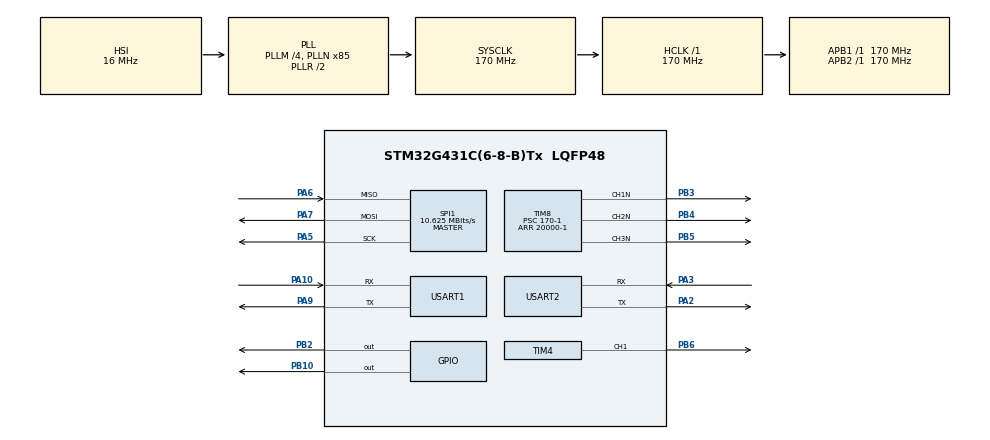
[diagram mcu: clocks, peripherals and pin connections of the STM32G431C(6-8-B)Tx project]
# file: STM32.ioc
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Dma.Request0=USART1_RX
Dma.USART1_RX.0.Direction=DMA_PERIPH_TO_MEMORY
Dma.USART1_RX.0.EventEnable=DISABLE
Dma.USART1_RX.0.Instance=DMA1_Channel1
Dma.USART1_RX.0.MemDataAlignment=DMA_MDATAALIGN_BYTE
Dma.USART1_RX.0.MemInc=DMA_MINC_ENABLE
Dma.USART1_RX.0.Mode=DMA_CIRCULAR
Dma.USART1_RX.0.PeriphDataAlignment=DMA_PDATAALIGN_BYTE
Dma.USART1_RX.0.PeriphInc=DMA_PINC_DISABLE
Dma.USART1_RX.0.Polarity=HAL_DMAMUX_REQ_GEN_RISING
Dma.USART1_RX.0.Priority=DMA_PRIORITY_LOW
Dma.USART1_RX.0.RequestNumber=1
Dma.USART1_RX.0.SignalID=NONE
Dma.USART1_RX.0.SyncEnable=DISABLE
Dma.USART1_RX.0.SyncPolarity=HAL_DMAMUX_SYNC_NO_EVENT
Dma.USART1_RX.0.SyncRequestNumber=1
Dma.USART1_RX.0.SyncSignalID=NONE
Mcu.Family=STM32G4
Mcu.Name=STM32G431C(6-8-B)Tx
Mcu.Package=LQFP48
NVIC.DMA1_Channel1_IRQn=true\:0\:0\:false\:false\:true\:false\:true\:true
NVIC.PriorityGroup=NVIC_PRIORITYGROUP_4
NVIC.USART1_IRQn=true\:0\:0\:false\:false\:true\:true\:true\:true
PA10.Mode=Asynchronous
PA10.Signal=USART1_RX
PA13.Mode=Serial_Wire
PA13.Signal=SYS_JTMS-SWDIO
PA14.Mode=Serial_Wire
PA14.Signal=SYS_JTCK-SWCLK
PA2.Mode=Asynchronous
PA2.Signal=USART2_TX
PA3.Mode=Asynchronous
PA3.Signal=USART2_RX
PA5.Mode=Full_Duplex_Master
PA5.Signal=SPI1_SCK
PA6.Mode=Full_Duplex_Master
PA6.Signal=SPI1_MISO
PA7.Mode=Full_Duplex_Master
PA7.Signal=SPI1_MOSI
PA9.Mode=Asynchronous
PA9.Signal=USART1_TX
PB10.Signal=GPIO_Output
PB2.Signal=GPIO_Output
PB3.Mode=PWM Generation1 CH1N
PB3.Signal=TIM8_CH1N
PB4.Mode=PWM Generation2 CH2N
PB4.Signal=TIM8_CH2N
PB5.Mode=PWM Generation3 CH3N
PB5.Signal=TIM8_CH3N
PB6.Signal=S_TIM4_CH1
PF0-OSC_IN.Mode=HSE-External-Oscillator
PF0-OSC_IN.Signal=RCC_OSC_IN
PF1-OSC_OUT.Mode=HSE-External-Oscillator
PF1-OSC_OUT.Signal=RCC_OSC_OUT
ProjectManager.HeapSize=0x200
ProjectManager.StackSize=0x400
ProjectManager.TargetToolchain=CMake
RCC.ADC12Freq_Value=170000000
RCC.AHBFreq_Value=170000000
RCC.APB1Freq_Value=170000000
RCC.APB1TimFreq_Value=170000000
RCC.APB2Freq_Value=170000000
RCC.APB2TimFreq_Value=170000000
RCC.CortexFreq_Value=170000000
RCC.EXTERNAL_CLOCK_VALUE=12288000
RCC.HCLKFreq_Value=170000000
RCC.HSE_VALUE=12000000
RCC.HSI48_VALUE=48000000
RCC.HSI_VALUE=16000000
RCC.LSE_VALUE=32768
RCC.PLLM=RCC_PLLM_DIV4
RCC.PLLN=85
RCC.SYSCLKFreq_VALUE=170000000
RCC.SYSCLKSource=RCC_SYSCLKSOURCE_PLLCLK
RCC.USBFreq_Value=170000000
RCC.VCOOutputFreq_Value=340000000
SH.S_TIM4_CH1.0=TIM4_CH1,PWM Generation1 CH1
SPI1.BaudRatePrescaler=SPI_BAUDRATEPRESCALER_16
SPI1.CalculateBaudRate=10.625 MBits/s
SPI1.DataSize=SPI_DATASIZE_8BIT
SPI1.Direction=SPI_DIRECTION_2LINES
SPI1.Mode=SPI_MODE_MASTER
SPI1.VirtualType=VM_MASTER
TIM4.Channel-PWM\ Generation1\ CH1=TIM_CHANNEL_1
TIM4.PeriodNoDither=20000-1
TIM4.Prescaler=170-1
TIM8.Channel-PWM\ Generation1\ CH1N=TIM_CHANNEL_1
TIM8.Channel-PWM\ Generation2\ CH2N=TIM_CHANNEL_2
TIM8.Channel-PWM\ Generation3\ CH3N=TIM_CHANNEL_3
TIM8.PeriodNoDither=20000-1
TIM8.Prescaler=170-1
USART1.VirtualMode-Asynchronous=VM_ASYNC
USART2.VirtualMode-Asynchronous=VM_ASYNC
VP_SYS_VS_DBSignals.Mode=DisableDeadBatterySignals
board=custom

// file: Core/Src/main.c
/* USER CODE BEGIN Header */
/**
  ******************************************************************************
  * @file           : main.c
  * @brief          : Main program body
  ******************************************************************************
  * @attention
  *
  * Copyright (c) 2026 STMicroelectronics.
  * All rights reserved.
  *
  * This software is licensed under terms that can be found in the LICENSE file
  * in the root directory of this software component.
  * If no LICENSE file comes with this software, it is provided AS-IS.
  *
  ******************************************************************************
  */
/* USER CODE END Header */
#include "main.h"
#include "dma.h"
#include "spi.h"
#include "tim.h"
#include "usart.h"
#include "gpio.h"

/* USER CODE BEGIN Includes */
#include "guidance_controller.h"
#include <stdio.h>
/* USER CODE END Includes */

/* USER CODE BEGIN PV */
static GuidanceController_t guidance_controller;
/* USER CODE END PV */

void SystemClock_Config(void);
/* USER CODE BEGIN PFP */
int _write(int file, char *ptr, int len)
{
    HAL_UART_Transmit(&huart2, (uint8_t *)ptr, len, HAL_MAX_DELAY);
    return len;
}
/* USER CODE END PFP */

int main(void)
{

  /* MCU Configuration--------------------------------------------------------*/

  /* Reset of all peripherals, Initializes the Flash interface and the Systick. */
  HAL_Init();

  /* Configure the system clock */
  SystemClock_Config();

  /* Initialize all configured peripherals */
  MX_GPIO_Init();
  MX_DMA_Init();
  MX_TIM4_Init();
  MX_TIM8_Init();
  MX_SPI1_Init();
  MX_USART1_UART_Init();
  MX_USART2_UART_Init();
  /* USER CODE BEGIN 2 */
  GuidanceController_Config_t guidance_config;

  GuidanceController_LoadDefaultConfig(&guidance_config);
  GuidanceController_Init(&guidance_controller, &huart1, &guidance_config);
  /* USER CODE END 2 */

  /* Infinite loop */
  while (1)
  {

    /* USER CODE BEGIN 3 */
    GuidanceController_RunOnce(&guidance_controller);
    HAL_Delay(GUIDANCE_CONTROLLER_LOOP_PERIOD_MS);
  }
  /* USER CODE END 3 */
}

void SystemClock_Config(void)
{
  RCC_OscInitTypeDef RCC_OscInitStruct = {0};
  RCC_ClkInitTypeDef RCC_ClkInitStruct = {0};

  /** Configure the main internal regulator output voltage
  */
  HAL_PWREx_ControlVoltageScaling(PWR_REGULATOR_VOLTAGE_SCALE1_BOOST);

  /** Initializes the RCC_Oscillators according to the specified parameters
  * in the RCC_OscInitTypeDef structure.
  */
  RCC_OscInitStruct.OscillatorType = RCC_OSCILLATORTYPE_HSI;
  RCC_OscInitStruct.HSIState = RCC_HSI_ON;
  RCC_OscInitStruct.HSICalibrationValue = RCC_HSICALIBRATION_DEFAULT;
  RCC_OscInitStruct.PLL.PLLState = RCC_PLL_ON;
  RCC_OscInitStruct.PLL.PLLSource = RCC_PLLSOURCE_HSI;
  RCC_OscInitStruct.PLL.PLLM = RCC_PLLM_DIV4;
  RCC_OscInitStruct.PLL.PLLN = 85;
  RCC_OscInitStruct.PLL.PLLP = RCC_PLLP_DIV2;
  RCC_OscInitStruct.PLL.PLLQ = RCC_PLLQ_DIV2;
  RCC_OscInitStruct.PLL.PLLR = RCC_PLLR_DIV2;
  if (HAL_RCC_OscConfig(&RCC_OscInitStruct) != HAL_OK)
  {
    Error_Handler();
  }

  /** Initializes the CPU, AHB and APB buses clocks
  */
  RCC_ClkInitStruct.ClockType = RCC_CLOCKTYPE_HCLK|RCC_CLOCKTYPE_SYSCLK
                              |RCC_CLOCKTYPE_PCLK1|RCC_CLOCKTYPE_PCLK2;
  RCC_ClkInitStruct.SYSCLKSource = RCC_SYSCLKSOURCE_PLLCLK;
  RCC_ClkInitStruct.AHBCLKDivider = RCC_SYSCLK_DIV1;
  RCC_ClkInitStruct.APB1CLKDivider = RCC_HCLK_DIV1;
  RCC_ClkInitStruct.APB2CLKDivider = RCC_HCLK_DIV1;

  if (HAL_RCC_ClockConfig(&RCC_ClkInitStruct, FLASH_LATENCY_4) != HAL_OK)
  {
    Error_Handler();
  }
}

void Error_Handler(void)
{
  __disable_irq();
  while (1)
  {
  }
}
